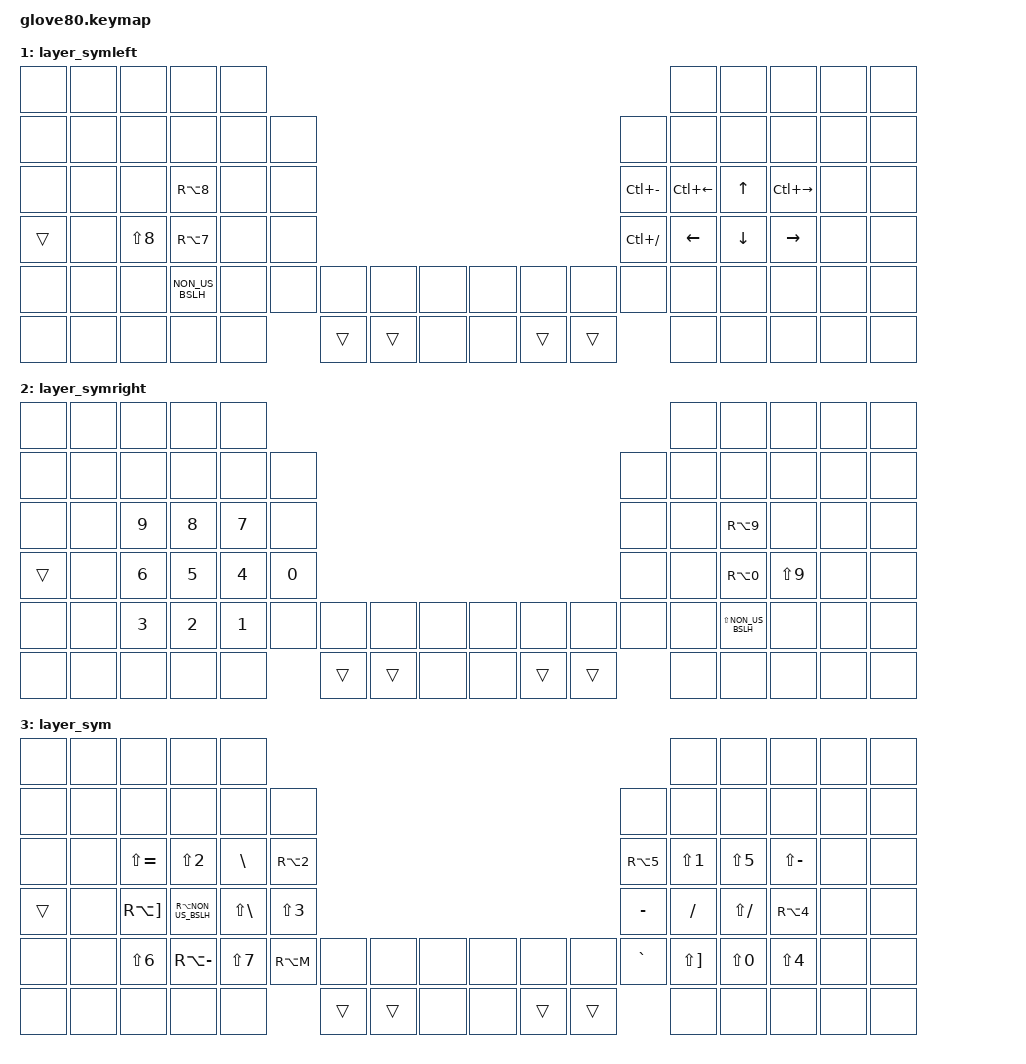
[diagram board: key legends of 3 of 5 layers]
/*
 * Copyright (c) 2020 The ZMK Contributors
 * Copyright (c) 2023 Innaworks Development Limited, trading as MoErgo
 *
 * SPDX-License-Identifier: MIT
 */

#include <behaviors.dtsi>
#include <dt-bindings/zmk/outputs.h>
#include <dt-bindings/zmk/keys.h>
#include <dt-bindings/zmk/bt.h>
#include <dt-bindings/zmk/rgb.h>

#define LAYER_Base     0
#define LAYER_symleft  1
#define LAYER_symright 2
#define LAYER_sym      3
#define LAYER_magic    4

/* To deal with the situation where there is no Lower layer, to keep &lower happy */
#ifndef LAYER_Lower
#define LAYER_Lower 0
#endif

/* Glove80 system behavior & macros */
/ {
    behaviors {
        // For the "layer" key, it'd nice to be able to use it as either a shift or a toggle.
        // Configure it as a tap dance, so the first tap (or hold) is a &mo and the second tap is a &to
        lower: lower {
            compatible = "zmk,behavior-tap-dance";
            label = "LAYER_TAP_DANCE";
            #binding-cells = <0>;
            tapping-term-ms = <200>;
            bindings = <&mo LAYER_Lower>, <&to LAYER_Lower>;
        };
    };
};

/ {
    macros {
        rgb_ug_status_macro: rgb_ug_status_macro {
            label = "RGB_UG_STATUS";
            compatible = "zmk,behavior-macro";
            #binding-cells = <0>;
            bindings
                = <&rgb_ug RGB_STATUS>;
        };
    };
};

/ {
#ifdef BT_DISC_CMD
    behaviors {
        bt_0: bt_0 {
            compatible = "zmk,behavior-tap-dance";
            label = "BT_0";
            #binding-cells = <0>;
            tapping-term-ms = <200>;
            bindings = <&bt_select_0>, <&bt BT_DISC 0>;
        };
        bt_1: bt_1 {
            compatible = "zmk,behavior-tap-dance";
            label = "BT_1";
            #binding-cells = <0>;
            tapping-term-ms = <200>;
            bindings = <&bt_select_1>, <&bt BT_DISC 1>;
        };
        bt_2: bt_2 {
            compatible = "zmk,behavior-tap-dance";
            label = "BT_2";
            #binding-cells = <0>;
            tapping-term-ms = <200>;
            bindings = <&bt_select_2>, <&bt BT_DISC 2>;
        };
        bt_3: bt_3 {
            compatible = "zmk,behavior-tap-dance";
            label = "BT_3";
            #binding-cells = <0>;
            tapping-term-ms = <200>;
            bindings = <&bt_select_3>, <&bt BT_DISC 3>;
        };
    };
    macros {
        bt_select_0: bt_select_0 {
            label = "BT_SELECT_0";
            compatible = "zmk,behavior-macro";
            #binding-cells = <0>;
            bindings
                = <&out OUT_BLE>,
                  <&bt BT_SEL 0>;
        };
        bt_select_1: bt_select_1 {
            label = "BT_SELECT_1";
            compatible = "zmk,behavior-macro";
            #binding-cells = <0>;
            bindings
                = <&out OUT_BLE>,
                  <&bt BT_SEL 1>;
        };
        bt_select_2: bt_select_2 {
            label = "BT_SELECT_2";
            compatible = "zmk,behavior-macro";
            #binding-cells = <0>;
            bindings
                = <&out OUT_BLE>,
                  <&bt BT_SEL 2>;
        };
        bt_select_3: bt_select_3 {
            label = "BT_SELECT_3";
            compatible = "zmk,behavior-macro";
            #binding-cells = <0>;
            bindings
                = <&out OUT_BLE>,
                  <&bt BT_SEL 3>;
        };
    };
#else
    macros {
        bt_0: bt_0 {
            label = "BT_0";
            compatible = "zmk,behavior-macro";
            #binding-cells = <0>;
            bindings
                = <&out OUT_BLE>,
                  <&bt BT_SEL 0>;
        };
        bt_1: bt_1 {
            label = "BT_1";
            compatible = "zmk,behavior-macro";
            #binding-cells = <0>;
            bindings
                = <&out OUT_BLE>,
                  <&bt BT_SEL 1>;
        };
        bt_2: bt_2 {
            label = "BT_2";
            compatible = "zmk,behavior-macro";
            #binding-cells = <0>;
            bindings
                = <&out OUT_BLE>,
                  <&bt BT_SEL 2>;
        };
        bt_3: bt_3 {
            label = "BT_3";
            compatible = "zmk,behavior-macro";
            #binding-cells = <0>;
            bindings
                = <&out OUT_BLE>,
                  <&bt BT_SEL 3>;
        };
    };
#endif
};

/ {
    behaviors {
        magic: magic {
            compatible = "zmk,behavior-hold-tap";
            label = "MAGIC_HOLD_TAP";
            #binding-cells = <2>;
            flavor = "tap-preferred";
            tapping-term-ms = <200>;
            bindings = <&mo>, <&rgb_ug_status_macro>;
        };
    };
};

/* #define for key positions */
#define POS_LH_T1 52
#define POS_LH_T2 53
#define POS_LH_T3 54
#define POS_LH_T4 69
#define POS_LH_T5 70
#define POS_LH_T6 71
#define POS_LH_C1R2 15
#define POS_LH_C1R3 27
#define POS_LH_C1R4 39
#define POS_LH_C1R5 51
#define POS_LH_C2R1 4
#define POS_LH_C2R2 14
#define POS_LH_C2R3 26
#define POS_LH_C2R4 38
#define POS_LH_C2R5 50
#define POS_LH_C2R6 68
#define POS_LH_C3R1 3
#define POS_LH_C3R2 13
#define POS_LH_C3R3 25
#define POS_LH_C3R4 37
#define POS_LH_C3R5 49
#define POS_LH_C3R6 67
#define POS_LH_C4R1 2
#define POS_LH_C4R2 12
#define POS_LH_C4R3 24
#define POS_LH_C4R4 36
#define POS_LH_C4R5 48
#define POS_LH_C4R6 66
#define POS_LH_C5R1 1
#define POS_LH_C5R2 11
#define POS_LH_C5R3 23
#define POS_LH_C5R4 35
#define POS_LH_C5R5 47
#define POS_LH_C5R6 65
#define POS_LH_C6R1 0
#define POS_LH_C6R2 10
#define POS_LH_C6R3 22
#define POS_LH_C6R4 34
#define POS_LH_C6R5 46
#define POS_LH_C6R6 64
#define POS_RH_T1 57
#define POS_RH_T2 56
#define POS_RH_T3 55
#define POS_RH_T4 74
#define POS_RH_T5 73
#define POS_RH_T6 72
#define POS_RH_C1R2 16
#define POS_RH_C1R3 28
#define POS_RH_C1R4 40
#define POS_RH_C1R5 58
#define POS_RH_C2R1 5
#define POS_RH_C2R2 17
#define POS_RH_C2R3 29
#define POS_RH_C2R4 41
#define POS_RH_C2R5 59
#define POS_RH_C2R6 75
#define POS_RH_C3R1 6
#define POS_RH_C3R2 18
#define POS_RH_C3R3 30
#define POS_RH_C3R4 42
#define POS_RH_C3R5 60
#define POS_RH_C3R6 76
#define POS_RH_C4R1 7
#define POS_RH_C4R2 19
#define POS_RH_C4R3 31
#define POS_RH_C4R4 43
#define POS_RH_C4R5 61
#define POS_RH_C4R6 77
#define POS_RH_C5R1 8
#define POS_RH_C5R2 20
#define POS_RH_C5R3 32
#define POS_RH_C5R4 44
#define POS_RH_C5R5 62
#define POS_RH_C5R6 78
#define POS_RH_C6R1 9
#define POS_RH_C6R2 21
#define POS_RH_C6R3 33
#define POS_RH_C6R4 45
#define POS_RH_C6R5 63
#define POS_RH_C6R6 79

/* Custom behaviors */
/ {
    behaviors {
      hm: homerow_mods {
        compatible = "zmk,behavior-hold-tap";
        #binding-cells = <2>;
        tapping-term-ms = <200>;
        quick-tap-ms = <0>;
        flavor = "tap-preferred";
        bindings = <&kp>, <&kp>;
      }; 
    };
};

/ {
    combos {
       compatible = "zmk,combos";
    };
};

// magic layer key
#define  K_MAGIC      &magic LAYER_magic 0
// keys in swedish/finnish keyboard
#define  SV_LPAREN    &kp LS(N8)            /* ( */
#define  SV_RPAREN    &kp LS(N9)            /* ) */
#define  SV_LBRACKET  &kp RA(N8)            /* [ */
#define  SV_RBRACKET  &kp RA(N9)            /* ] */
#define  SV_LBRACE    &kp RA(N7)            /* { */
#define  SV_RBRACE    &kp RA(N0)            /* } */
#define  SV_LT        &kp NON_US_BSLH       /* < */
#define  SV_GT        &kp LS(NON_US_BSLH)   /* > */
#define  SV_BACKTICK  &kp LS(EQUAL)         /* ` */
#define  SV_DQUOTE    &kp LS(N2)            /* " */
#define  SV_SQUOTE    &kp BSLH              /* ' */
#define  SV_AT        &kp RA(N2)            /* @ */
#define  SV_TILDE     &kp RA(RBKT)          /* ~ */
#define  SV_PIPE      &kp RA(NON_US_BSLH)   /* | */
#define  SV_ASTERISK  &kp LS(BSLH)          /* * */
#define  SV_HASH      &kp LS(N3)            /* # */
#define  SV_AMPERSAND &kp LS(N6)            /* & */
#define  SV_BSLASH    &kp LS(N7)            /* / */
#define  SV_FSLASH    &kp RA(MINUS)         /* \ */
#define  SV_PERMILLE  &kp RA(N5)            /* ‰ */
#define  SV_EXCLAM    &kp LS(N1)            /* ! */
#define  SV_PLUS      &kp MINUS             /* + */
#define  SV_MINUS     &kp FSLH              /* - */
#define  SV_USCORE    &kp LS(FSLH)          /* _ */
#define  SV_PERCENT   &kp LS(N5)            /* % */
#define  SV_QUESTION  &kp LS(MINUS)         /* ? */
#define  SV_DOLLAR    &kp RA(N4)            /* $ */
#define  SV_SECT      &kp GRAVE             /* § */
#define  SV_CARET     &kp LS(RBKT)          /* ^ */
#define  SV_EQ        &kp LS(N0)            /* = */
#define  SV_CURRENCY  &kp LS(N4)            /* ¤ */
#define  A_UMLAUT     SQT                   /* ä */
#define  O_UMLAUT     SEMI                  /* ö */
// other
#define  LAYER_BASE_THUMB_UPPER   &kp C_VOL_DN &kp C_VOL_UP &kp C_MUTE          &kp PSCRN    &kp DEL &kp INSERT
#define  LAYER_BASE_THUMB_LOWER   &kp SPACE    &kp ESC      &kp C_PLAY_PAUSE    &kp CAPSLOCK &kp ESC &kp RET
#define  KEYS_RGB_UPPER  &rgb_ug RGB_SPI &rgb_ug RGB_SAI &rgb_ug RGB_HUI &rgb_ug RGB_BRI &rgb_ug RGB_TOG
#define  KEYS_RGB_LOWER  &rgb_ug RGB_SPD &rgb_ug RGB_SAD &rgb_ug RGB_HUD &rgb_ug RGB_BRD &rgb_ug RGB_EFF

/ {
    keymap {
        compatible = "zmk,keymap";

        layer_Base {
            bindings = <
 &kp F2     &kp F3   &kp F4      &kp F5     &kp F6                                         &kp F7     &kp F8     &kp F9      &kp F10      &kp F11
 &kp F1     &kp N1   &kp N2      &kp N3     &kp N4     &kp N5                       &kp N6 &kp N7     &kp N8     &kp N9      &kp N0       &kp F12
 &kp TAB    &kp Q    &kp W       &kp F      &kp P      &kp B                        &kp J  &kp L      &kp U      &kp Y       &kp O_UMLAUT &none
 &kp BSPC   &lt 3 A  &hm LCTRL R &hm LALT S &lt 1 T    &kp G                        &kp M  &lt 2 N    &hm LALT E &hm LCTRL I &kp A_UMLAUT &kp O
 &kp LSHFT  &kp Z    &kp X       &kp C      &hm LGUI D &kp V LAYER_BASE_THUMB_UPPER &kp K  &hm LGUI H &kp COMMA  &kp DOT     &kp LBKT     &kp RSHFT
 K_MAGIC    &none    &none       &none      &none            LAYER_BASE_THUMB_LOWER        &none      &none      &none       &none        &none
            >;
        };

        layer_symleft {
            bindings = <
 &none   &none  &none        &none       &none                                                                 &none        &none    &none         &none   &none
 &none   &none  &none        &none       &none   &none                                           &none         &none        &none    &none         &none   &none
 &none   &none  &none        SV_LBRACKET &none   &none                                           &kp LC(MINUS) &kp LC(LEFT) &kp UP   &kp LC(RIGHT) &none   &none
 &trans  &none  SV_LPAREN    SV_LBRACE   &none   &none                                           &kp LC(FSLH)  &kp LEFT     &kp DOWN &kp RIGHT     &none   &none
 &none   &none  &none        SV_LT       &none   &none  &none  &none  &none &none &none  &none   &none         &none        &none    &none         &none   &none
 &none   &none  &none        &none       &none          &trans &trans &none &none &trans &trans                &none        &none    &none         &none   &none
            >;
        };

        layer_symright {
            bindings = <
 &none  &none &none  &none  &none                                                          &none &none        &none       &none &none
 &none  &none &none  &none  &none  &none                                           &none   &none &none        &none       &none &none
 &none  &none &kp N9 &kp N8 &kp N7 &none                                           &none   &none SV_RBRACKET  &none       &none &none
 &trans &none &kp N6 &kp N5 &kp N4 &kp N0                                          &none   &none SV_RBRACE    SV_RPAREN   &none &none
 &none  &none &kp N3 &kp N2 &kp N1 &none  &none  &none  &none &none &none  &none   &none   &none SV_GT        &none       &none &none
 &none  &none &none  &none  &none         &trans &trans &none &none &trans &trans          &none &none        &none       &none &none
            >;
        };

        layer_sym {
            bindings = <
 &none  &none &none         &none     &none                                                                     &none     &none      &none       &none &none
 &none  &none &none         &none     &none       &none                                             &none       &none     &none      &none       &none &none
 &none  &none SV_BACKTICK   SV_DQUOTE SV_SQUOTE   SV_AT                                             SV_PERMILLE SV_EXCLAM SV_PERCENT SV_QUESTION &none &none
 &trans &none SV_TILDE      SV_PIPE   SV_ASTERISK SV_HASH                                           SV_PLUS     SV_MINUS  SV_USCORE  SV_DOLLAR   &none &none
 &none  &none SV_AMPERSAND  SV_FSLASH SV_BSLASH   &kp RA(M) &none  &none  &none &none &none  &none  SV_SECT     SV_CARET  SV_EQ      SV_CURRENCY &none &none
 &none  &none &none         &none     &none                 &trans &trans &none &none &trans &trans             &none     &none      &none       &none &none
            >;
        };

        layer_magic {
            bindings = <
 &bt BT_CLR  &none &none &none &none                                                          &none &none &none &none &bt BT_CLR_ALL
 &none       &none &none &none &none &none                                              &none &none &none &none &none &none
 &none       KEYS_RGB_UPPER                                                             &none &none &none &none &none &none
 &bootloader KEYS_RGB_LOWER                                                             &none &none &none &none &none &bootloader
 &sys_reset  &none &none &none &none &none  &bt_2 &bt_3 &none        &none &none &none  &none &none &none &none &none &sys_reset
 &none &none &none &none &none              &bt_0 &bt_1 &out OUT_USB &none &none &none        &none &none &none &none &none
            >;
        };
    };
};
